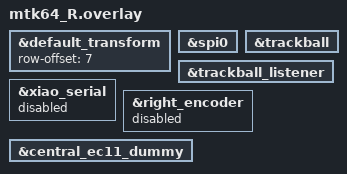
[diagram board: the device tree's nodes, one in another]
#include "mtk64.dtsi"
#include "mtk64_trackball.dtsi"

&default_transform {
    row-offset = <7>;
};

/*
&kscan0 {
    gpios
        = <&xiao_d 1 GPIO_ACTIVE_HIGH> 
        , <&xiao_d 2 GPIO_ACTIVE_HIGH> 
        , <&xiao_d 3 GPIO_ACTIVE_HIGH> 
        , <&xiao_d 6 GPIO_ACTIVE_HIGH>
        , <&xiao_d 7 GPIO_ACTIVE_HIGH> 
        , <&xiao_d 8 GPIO_ACTIVE_HIGH> 
        , <&xiao_d 9 GPIO_ACTIVE_HIGH> 	
    ;
};
*/

&spi0 {
    status = "okay";
};

&trackball { 
    status = "okay";
};

&trackball_listener {
    status = "okay";
};

&xiao_serial { status = "disabled"; };

// トラックボールと GPIO が競合するため右手側では right_encoder を無効のままにする
&right_encoder {
    status = "disabled";
};

// ZMK #2301: セントラル側で EC11 ドライバーを有効化 (左手エンコーダーの BLE 転送に必要)
&central_ec11_dummy {
    status = "okay";
};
